# CM41x_M0 register map
Vendor: Analog Devices; Series: CM41x_M0; File version: 1p0
CPU: CM0 r0p0, little endian, MPU, FPU, 4 interrupt priority bits
Registers are 32-bit, read-write, reset 0x0 unless marked. A register's access mark holds for its fields unless they carry their own. Offsets are from the block's base; [hi:lo] are bit positions; lines under a group give offsets from that group; {n}, {i} and the like mark numbered series; 'fields as' and 'values as' point back to an identical list.

## ADCC0 — ADC Controller
Base 0x4100B000
Same registers: ADCC1 0x4004A000
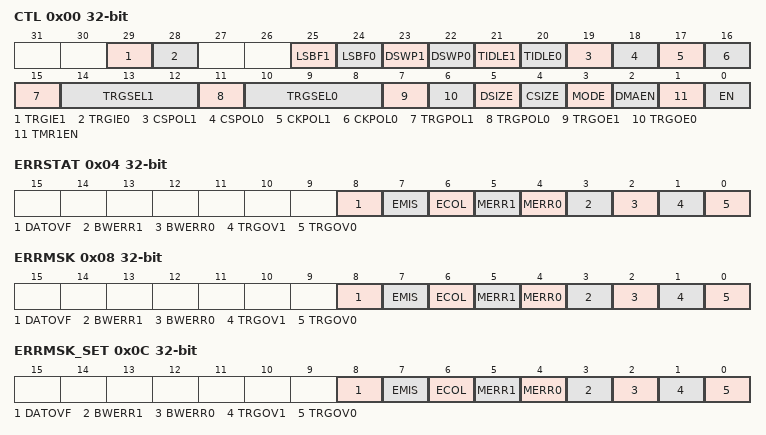
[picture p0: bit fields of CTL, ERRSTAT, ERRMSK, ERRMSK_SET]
0x00 CTL — Control Register
  [29] TRGIE1 — Trigger Input Enable 1
  [28] TRGIE0 — Trigger Input Enable 0
  [25] LSBF1 — LSB First 1
  [24] LSBF0 — LSB First 0
  [23] DSWP1 — Data Swap 1
  [22] DSWP0 — Data Swap 0
  [21] TIDLE1 — Transmit Idle 0
  [20] TIDLE0 — Transmit Idle 0
  [19] CSPOL1 — Chip Select Polarity 1
  [18] CSPOL0 — Chip Select Polarity 0
  [17] CKPOL1 — Clock Polarity 1
  [16] CKPOL0 — Clock Polarity 0
  [15] TRGPOL1 — Trigger Polarity 1
  [14:12] TRGSEL1 range 0x00000000..0x00000007 — Trigger Select 1
  [11] TRGPOL0 — Trigger Polarity 0
  [10:8] TRGSEL0 range 0x00000000..0x00000007 — Trigger Select 0
  [7] TRGOE1 — Trigger Output Enable 1
  [6] TRGOE0 — Trigger Output Enable 0
  [5] DSIZE — Data Size
  [4] CSIZE — Control Data Size
  [3] MODE — AFE Type Selection
  [2] DMAEN — DMA Enable
  [1] TMR1EN — Timer 1 Enable
  [0] EN — Enable ADCC Operation
0x04 ERRSTAT — Error Status Register
  [8] DATOVF ro — Event data Overflow Error Status
  [7] EMIS ro — Event Miss Error Status
  [6] ECOL ro — Event Collision Error Status
  [5] MERR1 — Memory Response Error 1 Status
  [4] MERR0 — Memory Response Error 0 Status
  [3] BWERR1 — Bandwidth Monitor Error 1 Status
  [2] BWERR0 — Bandwidth Monitor Error 0 Status
  [1] TRGOV1 — Trigger Overrun 1 Status
  [0] TRGOV0 — Trigger Overrun 0 Status
0x08 ERRMSK — Error Mask Register
  [8] DATOVF — Event data Overflow Error Mask
  [7] EMIS — Event Miss Error Mask
  [6] ECOL — Event Collision Error Mask
  [5] MERR1 — Memory Response Error 1 Mask
  [4] MERR0 — Memory Response Error 0 Mask
  [3] BWERR1 — Bandwidth Monitor Error 1 Mask
  [2] BWERR0 — Bandwidth Monitor Error 0 Mask
  [1] TRGOV1 — Trigger Overrun 1 Error Mask
  [0] TRGOV0 — Trigger Overrun 0 Error Mask
0x0C ERRMSK_SET — Error Mask Set Register
  [8] DATOVF range 0x00000000..0x00000001 — Event data Overflow Error Mask
  [7] EMIS range 0x00000000..0x00000001 — Event Miss Error Mask
  [6] ECOL range 0x00000000..0x00000001 — Event Collision Error Mask
  [5] MERR1 range 0x00000000..0x00000001 — Memory Response Error 1 Mask
  [4] MERR0 range 0x00000000..0x00000001 — Memory Response Error 0 Mask
  [3] BWERR1 range 0x00000000..0x00000001 — Bandwidth Monitor Error 1 Mask
  [2] BWERR0 range 0x00000000..0x00000001 — Bandwidth Monitor Error 0 Mask
  [1] TRGOV1 range 0x00000000..0x00000001 — Trigger Overrun 1 Error Mask
  [0] TRGOV0 range 0x00000000..0x00000001 — Trigger Overrun 0 Error Mask
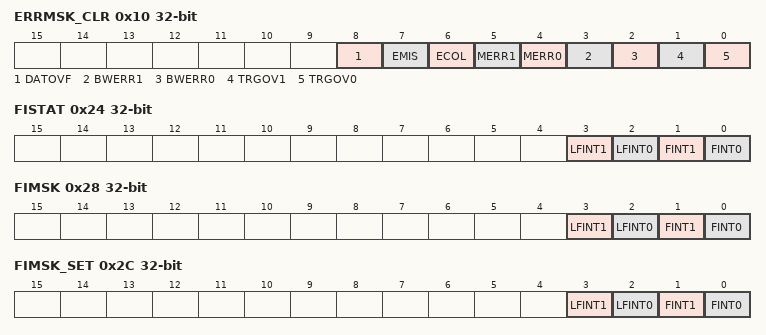
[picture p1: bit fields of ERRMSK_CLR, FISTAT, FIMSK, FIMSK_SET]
0x10 ERRMSK_CLR — Error Mask Clear Register
  fields as ERRMSK_SET
0x14 EISTAT — Event Interrupt Status Register
  [31:0] EVTnn — Event n Interrupt
0x18 EIMSK — Event Interrupt Mask Register
  [31:0] EVTnn — Event n Interrupt Mask
0x1C EIMSK_SET — Event Interrupt Mask Set Register
  [31:0] EVTnn range 0x00000000..0xFFFFFFFF — Event n Interrupt Mask
0x20 EIMSK_CLR — Event Interrupt Mask Clear Register
  [31:0] EVTnn range 0x00000000..0xFFFFFFFF — Event n Interrupt Mask
0x24 FISTAT — Frame Interrupt Status Register
  [3] LFINT1 range 0x00000000..0x00000001 — Last Frame Interrupt 1
  [2] LFINT0 range 0x00000000..0x00000001 — Last Frame Interrupt 0
  [1] FINT1 — Frame Interrupt 1
  [0] FINT0 — Frame Interrupt 0
0x28 FIMSK — Frame Interrupt Mask Register
  [3] LFINT1 range 0x00000000..0x00000001 — Last Frame Interrupt 1 Mask
  [2] LFINT0 range 0x00000000..0x00000001 — Last Frame Interrupt 0 Mask
  [1] FINT1 — Frame Interrupt 1 Mask
  [0] FINT0 — Frame Interrupt 0 Mask
0x2C FIMSK_SET — Frame Interrupt Mask Set Register
  [3] LFINT1 range 0x00000000..0x00000001 — Last Frame Interrupt 1 Mask
  [2] LFINT0 range 0x00000000..0x00000001 — Last Frame Interrupt 0 Mask
  [1] FINT1 range 0x00000000..0x00000001 — Frame Interrupt 1 Mask
  [0] FINT0 range 0x00000000..0x00000001 — Frame Interrupt 0 Mask
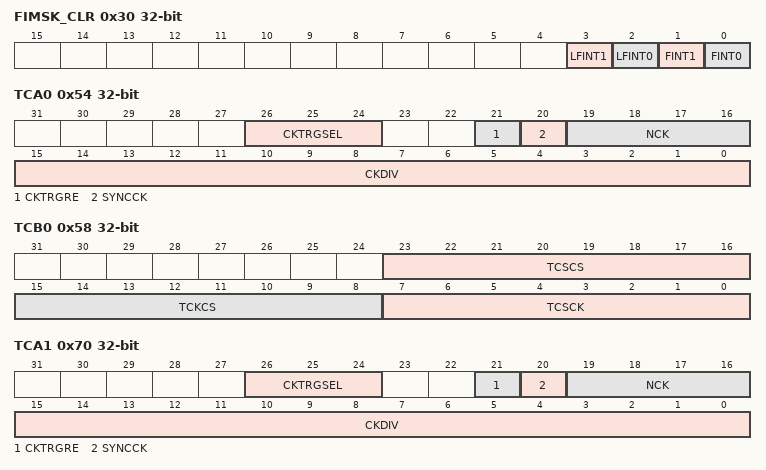
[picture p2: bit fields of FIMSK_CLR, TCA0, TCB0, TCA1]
0x30 FIMSK_CLR — Frame Interrupt Mask Clear Register
  fields as FIMSK_SET
0x34 EVTEN — Event Enable Register
  [31:0] EVTnn — Event n Enable
0x38 EVTEN_SET — Event Enable Set Register
  [31:0] EVTnn range 0x00000000..0xFFFFFFFF — Event n Enable
0x3C EVTEN_CLR — Event Enable Clear Register
  [31:0] EVTnn range 0x00000000..0xFFFFFFFF — Event n Enable
0x40 ECOL — Event Collision Status Register
  [31:0] EVT — Event n Collision Status
0x44 EMISS — Event Miss Status Register
  [31:0] EVTnn — Event n Miss Status
0x48 BPTR0 — Base Pointer 0 Register
  [31:0] VALUE range 0x00000000..0xFFFFFFFF — Base Pointer 0 Value
0x4C FRINC0 — Frame Increment 0 Register
  [31:0] VALUE range 0x00000000..0xFFFFFFFF — Frame Increment 0 Value
0x50 CBSIZ0 — Circular Buffer Size 0 Register
  [15:0] VALUE range 0x00000000..0x0000FFFF — Circular Buffer Size 0 Value
0x54 TCA0 — Timing Control A (ADC0) Register
  [26:24] CKTRGSEL range 0x00000000..0x00000007 — Trigger selection for SYNCCK feature
  [21] CKTRGRE range 0x00000000..0x00000001 — Trigger polarity for SYNCCK feature
  [20] SYNCCK range 0x00000000..0x00000001 — Enable bit for Clock synchronization based on trigger
  [19:16] NCK range 0x00000000..0x0000000F — Number of Clocks
  [15:0] CKDIV range 0x00000000..0x0000FFFF — Clock Divisor
0x58 TCB0 — Timing Control B (ADC0) Register
  [23:16] TCSCS range 0x00000000..0x000000FF — Timing CS to CS Delay
  [15:8] TCKCS range 0x00000000..0x000000FF — Time CK to CS Hold
  [7:0] TCSCK range 0x00000000..0x000000FF — Time CS to CK Setup
0x5C BWMON0 — Bandwidth Monitor 0 Register
  [31:0] CNT range 0x00000000..0xFFFFFFFF — Bandwidth Monitor Count
0x64 BPTR1 — DMA Base Pointer 1 Register
  [31:0] VALUE range 0x00000000..0xFFFFFFFF — Base Pointer 1 Value
0x68 FRINC1 — Frame Increment 1 Register
  [31:0] VALUE range 0x00000000..0xFFFFFFFF — Frame Increment 1 Value
0x6C CBSIZ1 — Circular Buffer Size 1 Register
  [15:0] VALUE range 0x00000000..0x0000FFFF — Circular Buffer Size 1 Value
0x70 TCA1 — Timing Control A (ADC1) Register
  fields as TCA0
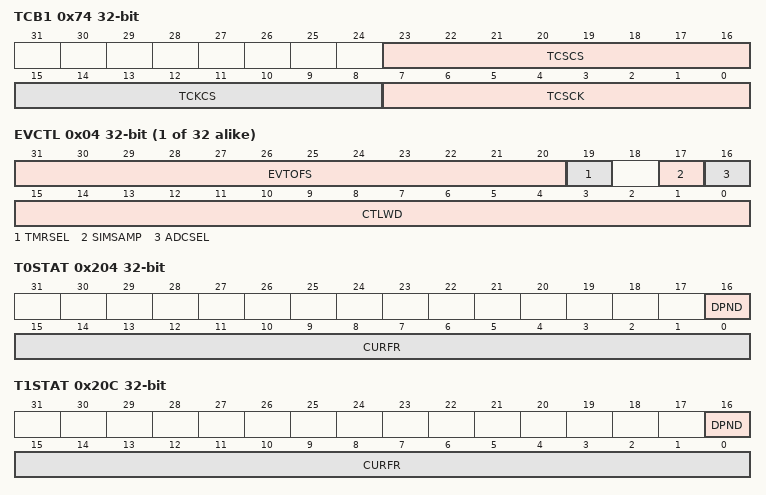
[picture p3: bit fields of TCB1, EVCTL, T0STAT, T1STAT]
0x74 TCB1 — Timing Control B (ADC1) Register
  fields as TCB0
0x78 BWMON1 — Bandwidth Monitor 1 Register
  [31:0] CNT range 0x00000000..0xFFFFFFFF — Bandwidth Monitor Count
{0x7C+8i} EVTn[{i}] (i=0..31) group — Event registers for each event
  0x00 EVT — Event n Time Register
    [31:0] TIME range 0x00000000..0xFFFFFFFF — Time Value
  0x04 EVCTL — Event n Control Register
    [31:20] EVTOFS range 0x00000000..0x00000FFF — Event Offset
    [19] TMRSEL — Timer Select.
    [17] SIMSAMP — Simultaneous Sampling Enable
    [16] ADCSEL — ADC Select
    [15:0] CTLWD range 0x00000000..0x0000FFFF — Control Word for ADC
0x17C NUMFRAM0 — Timer0 Frame Limit Count Register
  [15:0] VALUE range 0x00000000..0x0000FFFF — Number of TIMER frames
0x180 NUMFRAM1 — Timer1 Frame Limit Count Register
  [15:0] VALUE range 0x00000000..0x0000FFFF — Number of Timer Frames
0x184 DATOVF — Data Overflow Indication Register
  [31:0] EVT — Event n data Overflow Status
0x200 EPND — Pending Events Status Register
  [31:0] EVTnn ro — Event n Pending Status
0x204 T0STAT — Timer 0 Status Register
  [16] DPND ro — DMA Pending Status
  [15:0] CURFR ro — Current Frame Count
0x208 TMR0 — Timer 0 Current Count Register
  [31:0] CNT ro — Current Count of Timer 0
0x20C T1STAT — Timer 1 Status Register
  fields as T0STAT
0x210 TMR1 — Timer 1 Current Count Register
  [31:0] CNT ro — Current Count of Timer 1
{0x214+4i} EVDAT[{i}] (i=0..31) — Event n Data Register
  [15:0] VALUE ro — Event Data Sampled from ADC
{0x294+4i} EVSTAT[{i}] (i=0..31) — Event n Status Register
  [15:0] DLYCNT ro — Delay Count
0x314 CBNUM0 — Timer0 Circular Buffer DMA Wrap Number Register
  [15:0] VALUE ro — CB Value
0x318 CBNUM1 — Timer1 Circular Buffer DMA Wrap Number Register
  [15:0] VALUE ro — CB Value
0x31C TRGCNT0 — Trigger Count TIMER0 Register
  [15:0] TRGCNT ro — Trigger Count
0x320 TRGCNT1 — Trigger Count TIMER1 Register
  [15:0] TRGCNT ro — Trigger Count
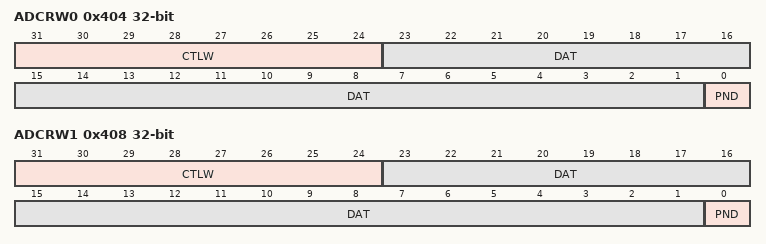
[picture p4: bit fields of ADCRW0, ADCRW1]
0x404 ADCRW0 — ADC2 Interface RW Access Register
  [31:24] CTLW range 0x00000000..0x000000FF — Control Word Sent to the ADC
  [23:1] DAT range 0x00000000..0x007FFFFF — Read/Write data
  [0] PND ro — Pending read/write status bit
0x408 ADCRW1 — ADC2 Interface RW Access Register
  fields as ADCRW0
